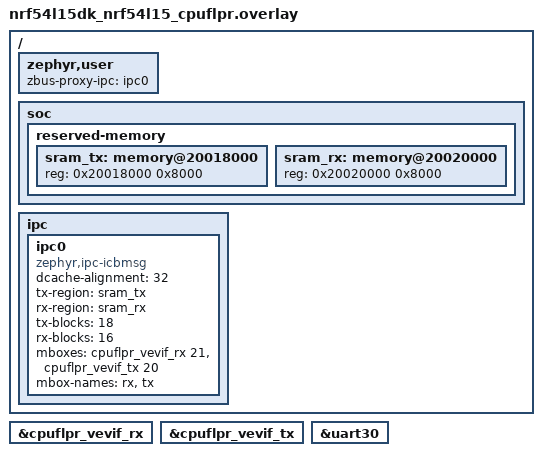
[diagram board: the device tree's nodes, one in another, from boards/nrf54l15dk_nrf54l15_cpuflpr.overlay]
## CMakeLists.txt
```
#
# Copyright (c) 2026 Nordic Semiconductor ASA
#
# SPDX-License-Identifier: Apache-2.0
#

cmake_minimum_required(VERSION 3.28.0)

find_package(Zephyr REQUIRED HINTS $ENV{ZEPHYR_BASE})
project(remote_cpurad)

zephyr_library_include_directories(src)

target_sources(app PRIVATE src/main.c)
```

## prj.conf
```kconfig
#
# Copyright (c) 2026 Nordic Semiconductor ASA
#
# SPDX-License-Identifier: Apache-2.0
#

CONFIG_LOG=y

CONFIG_TEST_RANDOM_GENERATOR=y

CONFIG_ZBUS=y
CONFIG_ZBUS_PROXY_AGENT=y

CONFIG_ZBUS_PROXY_AGENT_MAX_MESSAGE_SIZE=16
CONFIG_ZBUS_PROXY_AGENT_MAX_CHANNEL_NAME_SIZE=20

CONFIG_ZBUS_PROXY_AGENT_IPC=y
```

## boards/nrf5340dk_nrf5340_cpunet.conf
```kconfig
#
# Copyright (c) 2026 Nordic Semiconductor ASA
#
# SPDX-License-Identifier: Apache-2.0
#

CONFIG_HEAP_MEM_POOL_SIZE=4096

CONFIG_OPENAMP=y
CONFIG_OPENAMP_MASTER=n
```

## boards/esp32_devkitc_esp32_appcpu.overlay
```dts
/*
 * Copyright (c) 2026 Tomislav Milkovic <tomislav.milkovic95@gmail.com>
 * SPDX-License-Identifier: Apache-2.0
 */

/* Delete shm0 memory region to divide it into two parts: shm0_rx and shm0_tx */
/delete-node/ &shm0;

/ {
	zephyr,user {
		zbus-proxy-ipc = <&ipc0>;
	};

	chosen {
		/* Point to new IPC shared memory node to avoid build failure */
		zephyr,ipc_shm = &shm0_tx;
	};

	soc {
		shm0_rx: memory@3ffe5630 {
			compatible = "mmio-sram";
			reg = <0x3ffe5630 0x2000>;
		};

		shm0_tx: memory@3ffe7630 {
			compatible = "mmio-sram";
			reg = <0x3ffe7630 0x2000>;
		};
	};

	ipc {
		ipc0: ipc0 {
			compatible = "zephyr,ipc-icbmsg";
			dcache-alignment = <32>;
			tx-region = <&shm0_tx>;
			rx-region = <&shm0_rx>;
			tx-blocks = <32>;
			rx-blocks = <32>;
			mboxes = <&mbox0 1>, <&mbox0 0>;
			mbox-names = "tx", "rx";
			status = "okay";
		};
	};
};

&mbox0 {
	status = "okay";
};
```

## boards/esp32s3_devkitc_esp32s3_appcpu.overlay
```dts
/*
 * Copyright (c) 2026 Tomislav Milkovic <tomislav.milkovic95@gmail.com>
 * SPDX-License-Identifier: Apache-2.0
 */

/* Delete shm0 memory region to divide it into two parts: shm0_rx and shm0_tx */
/delete-node/ &shm0;

/ {
	zephyr,user {
		zbus-proxy-ipc = <&ipc0>;
	};

	chosen {
		/* Point to new IPC shared memory node to avoid build failure */
		zephyr,ipc_shm = &shm0_tx;
	};

	soc {
		shm0_rx: memory@3fce5400 {
			compatible = "mmio-sram";
			reg = <0x3fce5400 0x2000>;
		};

		shm0_tx: memory@3fce7400 {
			compatible = "mmio-sram";
			reg = <0x3fce7400 0x2000>;
		};
	};

	ipc {
		ipc0: ipc0 {
			compatible = "zephyr,ipc-icbmsg";
			dcache-alignment = <32>;
			tx-region = <&shm0_tx>;
			rx-region = <&shm0_rx>;
			tx-blocks = <32>;
			rx-blocks = <32>;
			mboxes = <&mbox0 1>, <&mbox0 0>;
			mbox-names = "tx", "rx";
			status = "okay";
		};
	};
};

&mbox0 {
	status = "okay";
};
```

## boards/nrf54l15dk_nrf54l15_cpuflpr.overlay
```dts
/*
 * Copyright (c) 2026 Nordic Semiconductor ASA
 *
 * SPDX-License-Identifier: Apache-2.0
 */

/ {
	zephyr,user {
		zbus-proxy-ipc = <&ipc0>;
	};

	soc {
		reserved-memory {
			#address-cells = <1>;
			#size-cells = <1>;

			sram_tx: memory@20018000 {
				reg = <0x20018000 0x8000>;
			};

			sram_rx: memory@20020000 {
				reg = <0x20020000 0x8000>;
			};
		};
	};

	ipc {
		ipc0: ipc0 {
			compatible = "zephyr,ipc-icbmsg";
			dcache-alignment = <32>;
			tx-region = <&sram_tx>;
			rx-region = <&sram_rx>;
			tx-blocks = <18>;
			rx-blocks = <16>;
			mboxes = <&cpuflpr_vevif_rx 21>, <&cpuflpr_vevif_tx 20>;
			mbox-names = "rx", "tx";
			status = "okay";
		};
	};
};

&cpuflpr_vevif_rx {
	status = "okay";
};

&cpuflpr_vevif_tx {
	status = "okay";
};

&uart30 {
	/delete-property/ hw-flow-control;
};
```

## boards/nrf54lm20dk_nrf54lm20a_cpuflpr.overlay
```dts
/*
 * Copyright (c) 2026 Nordic Semiconductor ASA
 *
 * SPDX-License-Identifier: Apache-2.0
 */

/ {
	zephyr,user {
		zbus-proxy-ipc = <&ipc0>;
	};

	soc {
		reserved-memory {
			#address-cells = <1>;
			#size-cells = <1>;

			sram_tx: memory@20057c00 {
				reg = <0x20057c00 0x8000>;
			};

			sram_rx: memory@2005fc00 {
				reg = <0x2005fc00 0x8000>;
			};
		};
	};

	ipc {
		ipc0: ipc0 {
			compatible = "zephyr,ipc-icbmsg";
			dcache-alignment = <32>;
			tx-region = <&sram_tx>;
			rx-region = <&sram_rx>;
			tx-blocks = <18>;
			rx-blocks = <16>;
			mboxes = <&cpuflpr_vevif_rx 21>, <&cpuflpr_vevif_tx 20>;
			mbox-names = "rx", "tx";
			status = "okay";
		};
	};
};

&cpuflpr_vevif_rx {
	status = "okay";
};

&cpuflpr_vevif_tx {
	status = "okay";
};

&uart30 {
	/delete-property/ hw-flow-control;
};
```

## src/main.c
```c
/*
 * Copyright (c) 2026 Nordic Semiconductor ASA
 *
 * SPDX-License-Identifier: Apache-2.0
 */

#include <zephyr/kernel.h>
#include <zephyr/logging/log.h>
#include <zephyr/random/random.h>
#include <zephyr/zbus/zbus.h>
#include <zephyr/zbus/proxy_agent/zbus_proxy_agent.h>
#include <zephyr/zbus/proxy_agent/zbus_proxy_agent_ipc.h>

LOG_MODULE_REGISTER(main, LOG_LEVEL_DBG);

/**
 * @brief Structure for the message data
 *
 * @note Must be kept in sync with the corresponding structure in the other domain to ensure correct
 * message parsing
 */
struct transfer_data {
	uint32_t test_value;
};

ZBUS_PROXY_AGENT_DEFINE(
	proxy_agent,                                     /* Proxy agent name */
	ZBUS_PROXY_AGENT_BACKEND_IPC,                    /* Proxy agent type */
	DT_PHANDLE(DT_PATH(zephyr_user), zbus_proxy_ipc) /* Backend node */
);

/**
 * Channel definitions
 * Channel request_channel is shadow channels, shadowing channel from domain A
 * Channel response_channel is origin channel, being forwarded to domain A
 */

ZBUS_SHADOW_CHAN_DEFINE(
	request_channel,      /* Chan name */
	struct transfer_data, /* Message type */

	proxy_agent,          /* Proxy agent name */
	NULL,                 /* User data */
	ZBUS_OBSERVERS_EMPTY, /* Observers */
	ZBUS_MSG_INIT(0)      /* Initial value */
);

ZBUS_CHAN_DEFINE(
	response_channel,     /* Chan name */
	struct transfer_data, /* Message type */

	NULL,                 /* Validator function */
	NULL,                 /* User data */
	ZBUS_OBSERVERS_EMPTY, /* Observers */
	ZBUS_MSG_INIT(0)      /* Initial value */
);

ZBUS_PROXY_ADD_CHAN(proxy_agent, response_channel);

/* Listen for requests on the request channel, and respond on the response channel */
static void ipc_forwarder_listener_cb(const struct zbus_channel *chan)
{
	int ret;
	const struct transfer_data *data = zbus_chan_const_msg(chan);
	struct transfer_data response = {
		/* Increment the received value for the response */
		.test_value = data->test_value + 1,
	};

	LOG_INF("Received message on channel %s. Test Value=%d", chan->name, data->test_value);

	LOG_INF("Sending response: Test Value=%d", response.test_value);

	ret = zbus_chan_pub(&response_channel, &response, K_MSEC(100));
	if (ret < 0) {
		LOG_ERROR("Failed to publish response on channel %s: %d", response_channel.name,
			  ret);
	} else {
		LOG_INF("Response published on channel %s", response_channel.name);
	}
}

ZBUS_LISTENER_DEFINE(ipc_forwarder_listener, ipc_forwarder_listener_cb);
ZBUS_CHAN_ADD_OBS(request_channel, ipc_forwarder_listener, 0);

int main(void)
{
	LOG_INF("ZBUS Proxy agent IPC Forwarder Sample Application");
	LOG_INF("Listening for requests on channel %s, responding on channel %s",
		request_channel.name, response_channel.name);

	return 0;
}
```
